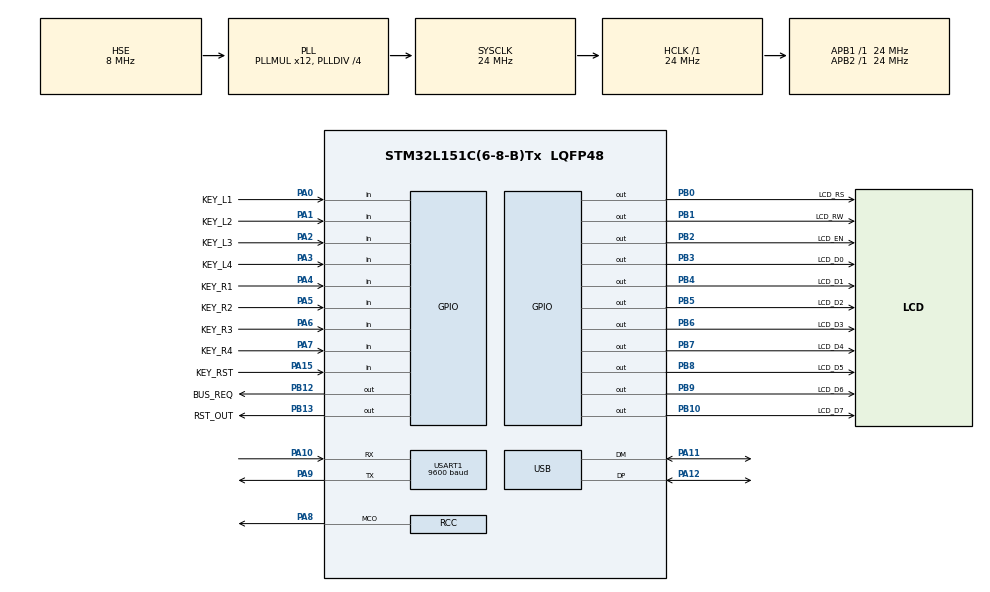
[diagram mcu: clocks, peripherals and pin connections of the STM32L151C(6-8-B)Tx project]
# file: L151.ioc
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Mcu.Family=STM32L1
Mcu.Name=STM32L151C(6-8-B)Tx
Mcu.Package=LQFP48
NVIC.PriorityGroup=NVIC_PRIORITYGROUP_4
NVIC.USB_LP_IRQn=true\:0\:0\:false\:false\:true
PA0-WKUP1.GPIO_Label=KEY_L1
PA0-WKUP1.GPIO_PuPd=GPIO_PULLUP
PA0-WKUP1.Signal=GPIO_Input
PA1.GPIO_Label=KEY_L2
PA1.GPIO_PuPd=GPIO_PULLUP
PA1.Signal=GPIO_Input
PA10.Mode=Asynchronous
PA10.Signal=USART1_RX
PA11.Mode=Device
PA11.Signal=USB_DM
PA12.Mode=Device
PA12.Signal=USB_DP
PA13.Mode=Serial_Wire
PA13.Signal=SYS_JTMS-SWDIO
PA14.Mode=Serial_Wire
PA14.Signal=SYS_JTCK-SWCLK
PA15.GPIO_Label=KEY_RST
PA15.Signal=GPIO_Input
PA2.GPIO_Label=KEY_L3
PA2.GPIO_PuPd=GPIO_PULLUP
PA2.Signal=GPIO_Input
PA3.GPIO_Label=KEY_L4
PA3.GPIO_PuPd=GPIO_PULLUP
PA3.Signal=GPIO_Input
PA4.GPIO_Label=KEY_R1
PA4.GPIO_PuPd=GPIO_PULLUP
PA4.Signal=GPIO_Input
PA5.GPIO_Label=KEY_R2
PA5.GPIO_PuPd=GPIO_PULLUP
PA5.Signal=GPIO_Input
PA6.GPIO_Label=KEY_R3
PA6.GPIO_PuPd=GPIO_PULLUP
PA6.Signal=GPIO_Input
PA7.GPIO_Label=KEY_R4
PA7.GPIO_PuPd=GPIO_PULLUP
PA7.Signal=GPIO_Input
PA8.GPIO_PuPd=GPIO_PULLDOWN
PA8.GPIO_Speed=GPIO_SPEED_FREQ_VERY_HIGH
PA8.Mode=Clock-out
PA8.Signal=RCC_MCO
PA9.Mode=Asynchronous
PA9.Signal=USART1_TX
PB0.GPIO_Label=LCD_RS
PB0.GPIO_ModeDefaultOutputPP=GPIO_MODE_OUTPUT_OD
PB0.GPIO_Speed=GPIO_SPEED_FREQ_VERY_HIGH
PB0.PinState=GPIO_PIN_SET
PB0.Signal=GPIO_Output
PB1.GPIO_Label=LCD_RW
PB1.GPIO_ModeDefaultOutputPP=GPIO_MODE_OUTPUT_OD
PB1.GPIO_Speed=GPIO_SPEED_FREQ_VERY_HIGH
PB1.PinState=GPIO_PIN_SET
PB1.Signal=GPIO_Output
PB10.GPIO_Label=LCD_D7
PB10.GPIO_ModeDefaultOutputPP=GPIO_MODE_OUTPUT_OD
PB10.GPIO_Speed=GPIO_SPEED_FREQ_VERY_HIGH
PB10.PinState=GPIO_PIN_SET
PB10.Signal=GPIO_Output
PB12.GPIO_Label=BUS_REQ
PB12.GPIO_ModeDefaultOutputPP=GPIO_MODE_OUTPUT_OD
PB12.GPIO_PuPd=GPIO_NOPULL
PB12.GPIO_Speed=GPIO_SPEED_FREQ_VERY_HIGH
PB12.PinState=GPIO_PIN_SET
PB12.Signal=GPIO_Output
PB13.GPIO_Label=RST_OUT
PB13.GPIO_PuPd=GPIO_PULLDOWN
PB13.GPIO_Speed=GPIO_SPEED_FREQ_VERY_HIGH
PB13.Signal=GPIO_Output
PB2.GPIO_Label=LCD_EN
PB2.GPIO_ModeDefaultOutputPP=GPIO_MODE_OUTPUT_OD
PB2.GPIO_Speed=GPIO_SPEED_FREQ_VERY_HIGH
PB2.PinState=GPIO_PIN_SET
PB2.Signal=GPIO_Output
PB3.GPIO_Label=LCD_D0
PB3.GPIO_ModeDefaultOutputPP=GPIO_MODE_OUTPUT_OD
PB3.GPIO_Speed=GPIO_SPEED_FREQ_VERY_HIGH
PB3.PinState=GPIO_PIN_SET
PB3.Signal=GPIO_Output
PB4.GPIO_Label=LCD_D1
PB4.GPIO_ModeDefaultOutputPP=GPIO_MODE_OUTPUT_OD
PB4.GPIO_Speed=GPIO_SPEED_FREQ_VERY_HIGH
PB4.PinState=GPIO_PIN_SET
PB4.Signal=GPIO_Output
PB5.GPIO_Label=LCD_D2
PB5.GPIO_ModeDefaultOutputPP=GPIO_MODE_OUTPUT_OD
PB5.GPIO_Speed=GPIO_SPEED_FREQ_VERY_HIGH
PB5.PinState=GPIO_PIN_SET
PB5.Signal=GPIO_Output
PB6.GPIO_Label=LCD_D3
PB6.GPIO_ModeDefaultOutputPP=GPIO_MODE_OUTPUT_OD
PB6.GPIO_Speed=GPIO_SPEED_FREQ_VERY_HIGH
PB6.PinState=GPIO_PIN_SET
PB6.Signal=GPIO_Output
PB7.GPIO_Label=LCD_D4
PB7.GPIO_ModeDefaultOutputPP=GPIO_MODE_OUTPUT_OD
PB7.GPIO_Speed=GPIO_SPEED_FREQ_VERY_HIGH
PB7.PinState=GPIO_PIN_SET
PB7.Signal=GPIO_Output
PB8.GPIO_Label=LCD_D5
PB8.GPIO_ModeDefaultOutputPP=GPIO_MODE_OUTPUT_OD
PB8.GPIO_Speed=GPIO_SPEED_FREQ_VERY_HIGH
PB8.PinState=GPIO_PIN_SET
PB8.Signal=GPIO_Output
PB9.GPIO_Label=LCD_D6
PB9.GPIO_ModeDefaultOutputPP=GPIO_MODE_OUTPUT_OD
PB9.GPIO_Speed=GPIO_SPEED_FREQ_VERY_HIGH
PB9.PinState=GPIO_PIN_SET
PB9.Signal=GPIO_Output
PC14-OSC32_IN.Mode=LSE-External-Oscillator
PC14-OSC32_IN.Signal=RCC_OSC32_IN
PC15-OSC32_OUT.Mode=LSE-External-Oscillator
PC15-OSC32_OUT.Signal=RCC_OSC32_OUT
PH0-OSC_IN.Mode=HSE-External-Oscillator
PH0-OSC_IN.Signal=RCC_OSC_IN
PH1-OSC_OUT.Mode=HSE-External-Oscillator
PH1-OSC_OUT.Signal=RCC_OSC_OUT
ProjectManager.HeapSize=0x200
ProjectManager.StackSize=0x400
ProjectManager.TargetToolchain=SW4STM32
RCC.AHBFreq_Value=24000000
RCC.APB1Freq_Value=24000000
RCC.APB1TimFreq_Value=24000000
RCC.APB2Freq_Value=24000000
RCC.APB2TimFreq_Value=24000000
RCC.HCLKFreq_Value=24000000
RCC.HSE_VALUE=8000000
RCC.HSI_VALUE=16000000
RCC.MSI_VALUE=2097000
RCC.PLLDIV=RCC_PLL_DIV4
RCC.PLLMUL=RCC_PLL_MUL12
RCC.RCC_MCODiv=RCC_MCODIV_2
RCC.RCC_MCOSource=RCC_MCO1SOURCE_PLLCLK
RCC.SYSCLKFreq_VALUE=24000000
RCC.SYSCLKSource=RCC_SYSCLKSOURCE_PLLCLK
RCC.USBOutput=48000000
RCC.VCOOutputFreq_Value=96000000
USART1.BaudRate=9600
USB_DEVICE.CLASS_NAME_FS=CDC
USB_DEVICE.MANUFACTURER_STRING=NSDN
USB_DEVICE.PRODUCT_STRING_CDC_FS=NSDN Quad CDC
USB_DEVICE.SERIALNUMBER_STRING_CDC_FS=000000000032
USB_DEVICE.USBD_HandleTypeDef=hUsbDeviceFS
USB_DEVICE.VirtualMode=Cdc
USB_DEVICE.VirtualModeFS=Cdc_FS
VP_USB_DEVICE_VS_USB_DEVICE_CDC_FS.Mode=CDC_FS
board=L151

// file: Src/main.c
/**
  ******************************************************************************
  * File Name          : main.c
  * Description        : Main program body
  ******************************************************************************
  *
  * Copyright (c) 2017 STMicroelectronics International N.V.
  * All rights reserved.
  *
  * Redistribution and use in source and binary forms, with or without
  * modification, are permitted, provided that the following conditions are met:
  *
  * 1. Redistribution of source code must retain the above copyright notice,
  *    this list of conditions and the following disclaimer.
  * 2. Redistributions in binary form must reproduce the above copyright notice,
  *    this list of conditions and the following disclaimer in the documentation
  *    and/or other materials provided with the distribution.
  * 3. Neither the name of STMicroelectronics nor the names of other
  *    contributors to this software may be used to endorse or promote products
  *    derived from this software without specific written permission.
  * 4. This software, including modifications and/or derivative works of this
  *    software, must execute solely and exclusively on microcontroller or
  *    microprocessor devices manufactured by or for STMicroelectronics.
  * 5. Redistribution and use of this software other than as permitted under
  *    this license is void and will automatically terminate your rights under
  *    this license.
  *
  * THIS SOFTWARE IS PROVIDED BY STMICROELECTRONICS AND CONTRIBUTORS "AS IS"
  * AND ANY EXPRESS, IMPLIED OR STATUTORY WARRANTIES, INCLUDING, BUT NOT
  * LIMITED TO, THE IMPLIED WARRANTIES OF MERCHANTABILITY, FITNESS FOR A
  * PARTICULAR PURPOSE AND NON-INFRINGEMENT OF THIRD PARTY INTELLECTUAL PROPERTY
  * RIGHTS ARE DISCLAIMED TO THE FULLEST EXTENT PERMITTED BY LAW. IN NO EVENT
  * SHALL STMICROELECTRONICS OR CONTRIBUTORS BE LIABLE FOR ANY DIRECT, INDIRECT,
  * INCIDENTAL, SPECIAL, EXEMPLARY, OR CONSEQUENTIAL DAMAGES (INCLUDING, BUT NOT
  * LIMITED TO, PROCUREMENT OF SUBSTITUTE GOODS OR SERVICES; LOSS OF USE, DATA,
  * OR PROFITS; OR BUSINESS INTERRUPTION) HOWEVER CAUSED AND ON ANY THEORY OF
  * LIABILITY, WHETHER IN CONTRACT, STRICT LIABILITY, OR TORT (INCLUDING
  * NEGLIGENCE OR OTHERWISE) ARISING IN ANY WAY OUT OF THE USE OF THIS SOFTWARE,
  * EVEN IF ADVISED OF THE POSSIBILITY OF SUCH DAMAGE.
  *
  ******************************************************************************
  */
#include "main.h"
#include "stm32l1xx_hal.h"
#include "usb_device.h"

UART_HandleTypeDef huart1;

/* USER CODE BEGIN PV */
/* Private variables ---------------------------------------------------------*/

/* USER CODE END PV */

void SystemClock_Config(void);
void Error_Handler(void);
static void MX_GPIO_Init(void);
static void MX_USART1_UART_Init(void);

/* USER CODE BEGIN PFP */
/* Private function prototypes -----------------------------------------------*/

/* USER CODE END PFP */

int main(void)
{

  /* MCU Configuration----------------------------------------------------------*/

  /* Reset of all peripherals, Initializes the Flash interface and the Systick. */
  HAL_Init();

  /* Configure the system clock */
  SystemClock_Config();

  /* Initialize all configured peripherals */
  MX_GPIO_Init();
  MX_USART1_UART_Init();
  MX_USB_DEVICE_Init();

  /* Infinite loop */
  /* USER CODE BEGIN WHILE */
  while (1)
  {
	  if (HAL_GPIO_ReadPin(KEY_RST_GPIO_Port, KEY_RST_Pin) == GPIO_PIN_RESET) {
		  while (HAL_GPIO_ReadPin(KEY_RST_GPIO_Port, KEY_RST_Pin) == GPIO_PIN_RESET);
		  HAL_GPIO_WritePin(RST_OUT_GPIO_Port, RST_OUT_Pin, GPIO_PIN_SET);
		  HAL_Delay(1000);
		  HAL_GPIO_WritePin(RST_OUT_GPIO_Port, RST_OUT_Pin, GPIO_PIN_RESET);
	  }
  /* USER CODE END WHILE */

  }

}

/** System Clock Configuration
*/
void SystemClock_Config(void)
{

  RCC_OscInitTypeDef RCC_OscInitStruct;
  RCC_ClkInitTypeDef RCC_ClkInitStruct;

    /**Configure the main internal regulator output voltage
    */
  __HAL_PWR_VOLTAGESCALING_CONFIG(PWR_REGULATOR_VOLTAGE_SCALE1);

    /**Initializes the CPU, AHB and APB busses clocks
    */
  RCC_OscInitStruct.OscillatorType = RCC_OSCILLATORTYPE_HSE;
  RCC_OscInitStruct.HSEState = RCC_HSE_ON;
  RCC_OscInitStruct.PLL.PLLState = RCC_PLL_ON;
  RCC_OscInitStruct.PLL.PLLSource = RCC_PLLSOURCE_HSE;
  RCC_OscInitStruct.PLL.PLLMUL = RCC_PLL_MUL12;
  RCC_OscInitStruct.PLL.PLLDIV = RCC_PLL_DIV4;
  if (HAL_RCC_OscConfig(&RCC_OscInitStruct) != HAL_OK)
  {
    Error_Handler();
  }

    /**Initializes the CPU, AHB and APB busses clocks
    */
  RCC_ClkInitStruct.ClockType = RCC_CLOCKTYPE_HCLK|RCC_CLOCKTYPE_SYSCLK
                              |RCC_CLOCKTYPE_PCLK1|RCC_CLOCKTYPE_PCLK2;
  RCC_ClkInitStruct.SYSCLKSource = RCC_SYSCLKSOURCE_PLLCLK;
  RCC_ClkInitStruct.AHBCLKDivider = RCC_SYSCLK_DIV1;
  RCC_ClkInitStruct.APB1CLKDivider = RCC_HCLK_DIV1;
  RCC_ClkInitStruct.APB2CLKDivider = RCC_HCLK_DIV1;

  if (HAL_RCC_ClockConfig(&RCC_ClkInitStruct, FLASH_LATENCY_1) != HAL_OK)
  {
    Error_Handler();
  }

  HAL_RCC_MCOConfig(RCC_MCO1, RCC_MCO1SOURCE_PLLCLK, RCC_MCODIV_2);

    /**Configure the Systick interrupt time
    */
  HAL_SYSTICK_Config(HAL_RCC_GetHCLKFreq()/1000);

    /**Configure the Systick
    */
  HAL_SYSTICK_CLKSourceConfig(SYSTICK_CLKSOURCE_HCLK);

  /* SysTick_IRQn interrupt configuration */
  HAL_NVIC_SetPriority(SysTick_IRQn, 0, 0);
}

/* USART1 init function */
static void MX_USART1_UART_Init(void)
{

  huart1.Instance = USART1;
  huart1.Init.BaudRate = 9600;
  huart1.Init.WordLength = UART_WORDLENGTH_8B;
  huart1.Init.StopBits = UART_STOPBITS_1;
  huart1.Init.Parity = UART_PARITY_NONE;
  huart1.Init.Mode = UART_MODE_TX_RX;
  huart1.Init.HwFlowCtl = UART_HWCONTROL_NONE;
  huart1.Init.OverSampling = UART_OVERSAMPLING_16;
  if (HAL_UART_Init(&huart1) != HAL_OK)
  {
    Error_Handler();
  }

}

/** Configure pins as
        * Analog
        * Input
        * Output
        * EVENT_OUT
        * EXTI
     PA8   ------> RCC_MCO
*/
static void MX_GPIO_Init(void)
{

  GPIO_InitTypeDef GPIO_InitStruct;

  /* GPIO Ports Clock Enable */
  __HAL_RCC_GPIOC_CLK_ENABLE();
  __HAL_RCC_GPIOH_CLK_ENABLE();
  __HAL_RCC_GPIOA_CLK_ENABLE();
  __HAL_RCC_GPIOB_CLK_ENABLE();

  /*Configure GPIO pins : KEY_L1_Pin KEY_L2_Pin KEY_L3_Pin KEY_L4_Pin
                           KEY_R1_Pin KEY_R2_Pin KEY_R3_Pin KEY_R4_Pin */
  GPIO_InitStruct.Pin = KEY_L1_Pin|KEY_L2_Pin|KEY_L3_Pin|KEY_L4_Pin
                          |KEY_R1_Pin|KEY_R2_Pin|KEY_R3_Pin|KEY_R4_Pin;
  GPIO_InitStruct.Mode = GPIO_MODE_INPUT;
  GPIO_InitStruct.Pull = GPIO_PULLUP;
  HAL_GPIO_Init(GPIOA, &GPIO_InitStruct);

  /*Configure GPIO pins : LCD_RS_Pin LCD_RW_Pin LCD_EN_Pin LCD_D7_Pin
                           BUS_REQ_Pin LCD_D0_Pin LCD_D1_Pin LCD_D2_Pin
                           LCD_D3_Pin LCD_D4_Pin LCD_D5_Pin LCD_D6_Pin */
  GPIO_InitStruct.Pin = LCD_RS_Pin|LCD_RW_Pin|LCD_EN_Pin|LCD_D7_Pin
                          |BUS_REQ_Pin|LCD_D0_Pin|LCD_D1_Pin|LCD_D2_Pin
                          |LCD_D3_Pin|LCD_D4_Pin|LCD_D5_Pin|LCD_D6_Pin;
  GPIO_InitStruct.Mode = GPIO_MODE_OUTPUT_OD;
  GPIO_InitStruct.Pull = GPIO_NOPULL;
  GPIO_InitStruct.Speed = GPIO_SPEED_FREQ_VERY_HIGH;
  HAL_GPIO_Init(GPIOB, &GPIO_InitStruct);

  /*Configure GPIO pin : RST_OUT_Pin */
  GPIO_InitStruct.Pin = RST_OUT_Pin;
  GPIO_InitStruct.Mode = GPIO_MODE_OUTPUT_PP;
  GPIO_InitStruct.Pull = GPIO_PULLDOWN;
  GPIO_InitStruct.Speed = GPIO_SPEED_FREQ_VERY_HIGH;
  HAL_GPIO_Init(RST_OUT_GPIO_Port, &GPIO_InitStruct);

  /*Configure GPIO pin : PA8 */
  GPIO_InitStruct.Pin = GPIO_PIN_8;
  GPIO_InitStruct.Mode = GPIO_MODE_AF_PP;
  GPIO_InitStruct.Pull = GPIO_PULLDOWN;
  GPIO_InitStruct.Speed = GPIO_SPEED_FREQ_VERY_HIGH;
  GPIO_InitStruct.Alternate = GPIO_AF0_MCO;
  HAL_GPIO_Init(GPIOA, &GPIO_InitStruct);

  /*Configure GPIO pin : KEY_RST_Pin */
  GPIO_InitStruct.Pin = KEY_RST_Pin;
  GPIO_InitStruct.Mode = GPIO_MODE_INPUT;
  GPIO_InitStruct.Pull = GPIO_NOPULL;
  HAL_GPIO_Init(KEY_RST_GPIO_Port, &GPIO_InitStruct);

  /*Configure GPIO pin Output Level */
  HAL_GPIO_WritePin(GPIOB, LCD_RS_Pin|LCD_RW_Pin|LCD_EN_Pin|LCD_D7_Pin
                          |BUS_REQ_Pin|LCD_D0_Pin|LCD_D1_Pin|LCD_D2_Pin
                          |LCD_D3_Pin|LCD_D4_Pin|LCD_D5_Pin|LCD_D6_Pin, GPIO_PIN_SET);

  /*Configure GPIO pin Output Level */
  HAL_GPIO_WritePin(RST_OUT_GPIO_Port, RST_OUT_Pin, GPIO_PIN_RESET);

}

void Error_Handler(void)
{
  while(1)
  {
  }
}

/************************ (C) COPYRIGHT STMicroelectronics *****END OF FILE****/
